# AT32UC3A1512 device description
Architecture: AVR32_UC3; Family: AVR UC3
Registers are 32-bit, read-write, reset 0x0 unless marked. A register's access mark holds for its fields unless they carry their own. Offsets are from the block's base; [hi:lo] are bit positions; lines under a group give offsets from that group; {n}, {i} and the like mark numbered series; 'fields as' and 'values as' point back to an identical list.

## PDCA — Peripheral DMA Controller
Instances: PDCA 0xffff0000
{0x0+0x40*i} channel[{i}] (i=0..31) group
  0x00 MAR — Memory Address Register
    [31:0] MADDR — Memory Address
  0x04 PSR — Peripheral Select Register
    [7:0] PID — Peripheral Identifier
  0x08 TCR — Transfer Counter Register
    [15:0] TCV — Transfer Counter Value
  0x0C MARR — Memory Address Reload Register
    [31:0] MARV — Memory Address Reload Value
  0x10 TCRR — Transfer Counter Reload Register
    [15:0] TCRV — Transfer Counter Reload Value
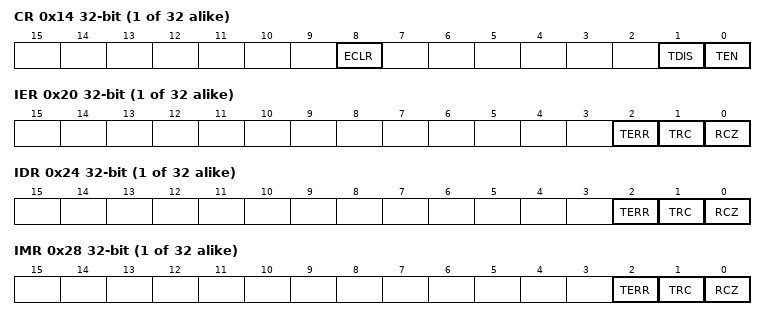
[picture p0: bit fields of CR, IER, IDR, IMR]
  0x14 CR wo — Control Register
    [8] ECLR — Error Clear
    [1] TDIS — Transfer Disable
    [0] TEN — Transfer Enable
  0x18 MR — Mode Register
    [1:0] SIZE — Transfer size
      0=Byte; 1=Half_Word; 2=Word
  0x1C SR ro — Status Register
    [0] TEN — Transfer Enabled
  0x20 IER wo — Interrupt Enable Register
    [2] TERR — Transfer Error
    [1] TRC — Transfer Complete
    [0] RCZ — Reload Counter Zero
  0x24 IDR wo — Interrupt Disable Register
    fields as channel[0].IER
  0x28 IMR ro — Interrupt Mask Register
    fields as channel[0].IER
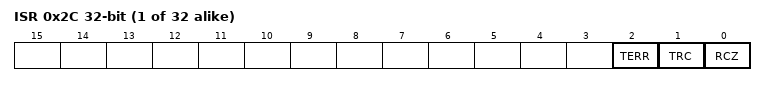
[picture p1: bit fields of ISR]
  0x2C ISR ro — Interrupt Status Register
    fields as channel[0].IER

## PWM — Pulse Width Modulation Controller
Instances: PWM 0xffff3000
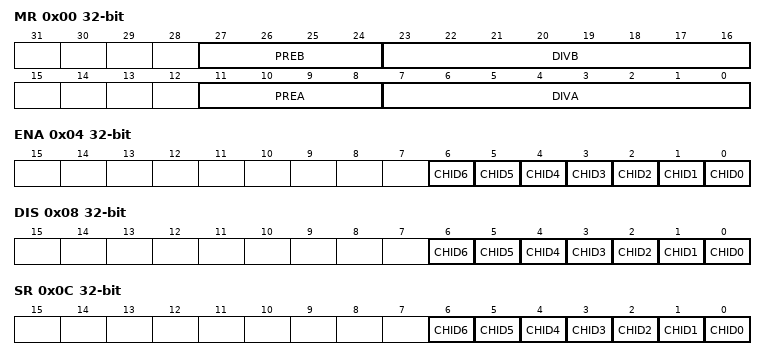
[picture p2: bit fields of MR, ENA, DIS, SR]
0x00 MR — PWM Mode Register
  [27:24] PREB
    0=MCK; 1=MCK_DIV_2; 2=MCK_DIV_4; 3=MCK_DIV_8; 4=MCK_DIV_16; 5=MCK_DIV_32; 6=MCK_DIV_64; 7=MCK_DIV_128; 8=MCK_DIV_256; 9=MCK_DIV_512; 10=MCK_DIV_1024
  [23:16] DIVB — CLKB divide factor
    0=CLK_OFF; 1=CLK_SEL_PREAB
  [11:8] PREA
    values as PREB
  [7:0] DIVA — CLKA divide factor
    0=CLK_OFF; 1=CLK_SEL_PREAB
0x04 ENA wo reset not defined — PWM Enable Register
  [n] CHID{n} (n=0..6) — Channel ID {n}
0x08 DIS wo reset not defined — PWM Disable Register
  [6] CHID6 — Channel ID 3
  [n] CHID{n} (n=0..5) — Channel ID {n}
0x0C SR ro — PWM Status Register
  [n] CHID{n} (n=0..6) — Channel ID {n}
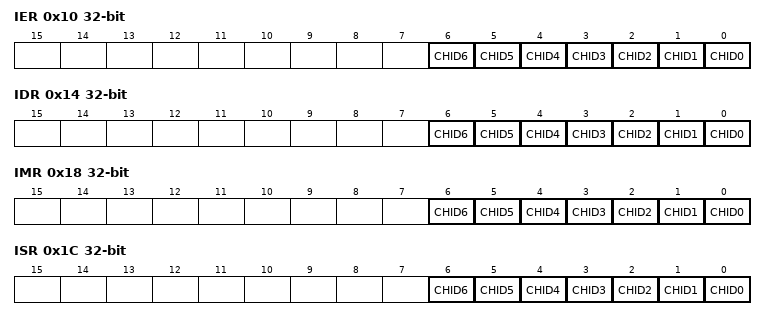
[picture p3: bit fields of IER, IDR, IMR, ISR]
0x10 IER wo reset not defined — PWM Interrupt Enable Register
  [n] CHID{n} (n=0..6) — Channel ID {n}
0x14 IDR wo reset not defined — PWM Interrupt Disable Register
  [n] CHID{n} (n=0..6) — Channel ID {n}
0x18 IMR ro — PWM Interrupt Mask Register
  [n] CHID{n} (n=0..6) — Channel ID {n}
0x1C ISR ro — PWM Interrupt Status Register
  [n] CHID{n} (n=0..6) — Channel ID {n}
{0x200+0x20*i} channel[{i}] (i=0..31) group
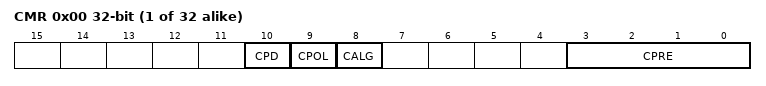
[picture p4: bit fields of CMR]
  0x00 CMR — PWM Channel Mode Register 0
    [10] CPD — Channel Update Period
    [9] CPOL — Channel Polarity
    [8] CALG — Channel Alignment
    [3:0] CPRE — Channel pre-scaler
      0=MCK; 1=MCK_DIV_2; 2=MCK_DIV_4; 3=MCK_DIV_8; 4=MCK_DIV_16; 5=MCK_DIV_32; 6=MCK_DIV_64; 7=MCK_DIV_128; 8=MCK_DIV_256; 9=MCK_DIV_512; 10=MCK_DIV_1024; 11=CLKA; 12=CLKB
  0x04 CDTY — PWM Channel Duty Cycle Register 0
    [31:0] CDTY — Channel Duty Cycle
  0x08 CPRD — PWM Channel Period Register 0
    [31:0] CPRD — Channel Period
  0x0C CCNT ro — PWM Channel Counter Register 0
    [31:0] CNT — Channel Counter Register
  0x10 CUPD wo reset not defined — PWM Channel Update Register 0

## RTC — Real Time Counter
Instances: RTC 0xffff0d00
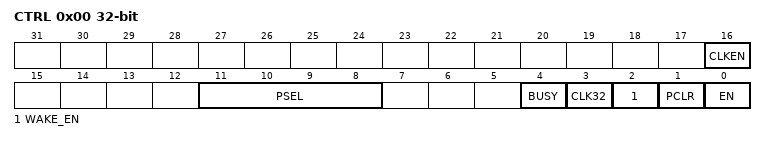
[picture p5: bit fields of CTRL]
0x00 CTRL — Real Time Counter Control
  [16] CLKEN — Clock enable
  [11:8] PSEL — Prescale Select
  [4] BUSY — Busy bit
  [3] CLK32 — Select 32KHz oscillator instead of RC Oscillator
  [2] WAKE_EN — Wake enable
  [1] PCLR — Prescaler Clear (strobe)
  [0] EN — Enable
0x04 VAL — RTC Value
0x08 TOP — RTC Top Value
  [31:0] VAL
0x10 IER wo — RTC Interrupt Enable Register
  [0] TOPI — TOP Interrupt
0x14 IDR wo — RTC Interrupt Disable Register
  [0] TOPI — TOP Interrupt
0x18 IMR ro — RTC Interrupt Mask Register
  [0] TOPI — TOP Interrupt
0x1C ISR ro — RTC Interrupt Status Register
  [0] TOPI — TOP Interrupt
0x20 ICR wo — RTC Interrupt Clear Register
  [0] TOPI — TOP Interrupt
